AUTOSAR XML (schema 00049)
package /Application/DltConfig
  dlt log channel to process mapping DltLogChannelToProcessMapping_SOA_DriverSeat_TO_SOA_DriverSeat: dlt-log-channel=SOA_DriverSeat, process=SOA_DriverSeat
package /Application/Executable
  executable SOA_DriverSeat: category=APPLICATION_LEVEL, logging-behavior=USES-LOGGING, reporting-behavior=REPORTS-EXECUTION-STATE, version=1.0.0
    root sw component prototype AA: application-type=SOA_DriverSeat
package /Application/Manifest
  service instance to port prototype mapping SOA_DriverSeat_AA_PPort_SOA_DriverSeat: port-prototype=AA.PPort_SOA_DriverSeat, process=SOA_DriverSeat, service-instance=Provider_SoaDriverSeat
  service instance to port prototype mapping SOA_DriverSeat_AA_RPort_Zone1DrvSeat: port-prototype=AA.RPort_Zone1DrvSeat, process=SOA_DriverSeat, service-instance=Consumer_Zone1DrvSeat
  service instance to port prototype mapping SOA_DriverSeat_AA_RPort_Zone1VehicleInfo: port-prototype=AA.RPort_Zone1VehicleInfo, process=SOA_DriverSeat, service-instance=Consumer_SoaDriverSeat_VehicleInfo
package /Application/Package/SOA_DriverSeat/SoftwareCluster_1_0_0
  software cluster SOA_DriverSeat_SoftwareCluster: category=APPLICATION_LAYER, contained-ar-element=SOA_DriverSeat, contained-package-element=[SOA_DriverSeat_AA_PPort_SOA_DriverSeat, SOA_DriverSeat_AA_RPort_Zone1DrvSeat], contained-process=SOA_DriverSeat, vendor-id=79, vendor-signature=ParaCertificate, version=1.0.0
package /Application/Package/SOA_DriverSeat/SoftwareCluster_1_0_1
  software cluster SOA_DriverSeat_SoftwareCluster: category=APPLICATION_LAYER, contained-ar-element=SOA_DriverSeat, contained-package-element=[SOA_DriverSeat_AA_PPort_SOA_DriverSeat, SOA_DriverSeat_AA_RPort_Zone1DrvSeat], contained-process=SOA_DriverSeat, vendor-id=79, vendor-signature=ParaCertificate, version=1.0.1
package /Application/Package/SOA_DriverSeat/SoftwareCluster_1_0_2
  software cluster SOA_DriverSeat_SoftwareCluster: category=APPLICATION_LAYER, contained-ar-element=SOA_DriverSeat, contained-package-element=[SOA_DriverSeat_AA_PPort_SOA_DriverSeat, SOA_DriverSeat_AA_RPort_Zone1DrvSeat], contained-process=SOA_DriverSeat, vendor-id=79, vendor-signature=ParaCertificate, version=1.0.2
package /Application/Package/SOA_DriverSeat/SoftwarePackage
  software package SOA_DriverSeat_InstallSoftwarePackage_1_0_0: action-type=INSTALL, compressed-software-package-size=0, maximum-supported-ucm-version=1.0.0, minimum-supported-ucm-version=1.0.0, packager-id=79, packager-signature=ParaCertificate, post-verification-reboot=false, pre-activate=SC.Off, pre-activation-reboot=false, software-cluster=SoftwareCluster_1_0_0/SOA_DriverSeat_SoftwareCluster, uncompressed-software-cluster-size=0, verify=SC.Verify
  software package SOA_DriverSeat_RemoveSoftwarePackage_1_0_2: action-type=REMOVE, compressed-software-package-size=0, maximum-supported-ucm-version=1.0.0, minimum-supported-ucm-version=1.0.0, packager-id=79, packager-signature=ParaCertificate, post-verification-reboot=false, pre-activate=SC.Off, pre-activation-reboot=false, software-cluster=SoftwareCluster_1_0_2/SOA_DriverSeat_SoftwareCluster, uncompressed-software-cluster-size=0, verify=SC.Verify
  software package SOA_DriverSeat_UpdateSoftwarePackage_1_0_1: action-type=UPDATE, compressed-software-package-size=0, maximum-supported-ucm-version=1.0.0, minimum-supported-ucm-version=1.0.0, packager-id=79, packager-signature=ParaCertificate, post-verification-reboot=false, pre-activate=SC.Off, pre-activation-reboot=false, software-cluster=SoftwareCluster_1_0_1/SOA_DriverSeat_SoftwareCluster, uncompressed-software-cluster-size=0, verify=SC.Verify
package /Application/Package/SOA_DriverSeat/VehiclePackage
  vehicle package SOA_DriverSeat_InstallVehiclePackage_1_0_0: vehicle-driver-notification{approval-required=true, notification-state=PROCESS}, packager-signature=ParaCertificate
    rollout-qualifications:
      vehicle rollout step RolloutQualification0
        ucm-processings:
          ucm step UcmProcessing0: ucm=SOA_DriverSeat_InstallVehiclePackage_1_0_0/EEVP_UCM
            software package step SoftwarePackageStep0: process=SOA_DriverSeat_InstallSoftwarePackage_1_0_0, transfers=software-package-storing={storing=UCM, transfer=SOA_DriverSeat_InstallSoftwarePackage_1_0_0}
    ucm description EEVP_UCM: identifier=EEVP_UCM
  vehicle package SOA_DriverSeat_RemoveVehiclePackage_1_0_2: vehicle-driver-notification{approval-required=true, notification-state=PROCESS}, packager-signature=ParaCertificate
    rollout-qualifications:
      vehicle rollout step RolloutQualification0
        ucm-processings:
          ucm step UcmProcessing0: ucm=SOA_DriverSeat_RemoveVehiclePackage_1_0_2/EEVP_UCM
            software package step SoftwarePackageStep0: process=SOA_DriverSeat_RemoveSoftwarePackage_1_0_2, transfers=software-package-storing={storing=UCM, transfer=SOA_DriverSeat_RemoveSoftwarePackage_1_0_2}
    ucm description EEVP_UCM: identifier=EEVP_UCM
  vehicle package SOA_DriverSeat_UpdateVehiclePackage_1_0_1: vehicle-driver-notification{approval-required=true, notification-state=PROCESS}, packager-signature=ParaCertificate
    rollout-qualifications:
      vehicle rollout step RolloutQualification0
        ucm-processings:
          ucm step UcmProcessing0: ucm=SOA_DriverSeat_UpdateVehiclePackage_1_0_1/EEVP_UCM
            software package step SoftwarePackageStep0: process=SOA_DriverSeat_UpdateSoftwarePackage_1_0_1, transfers=software-package-storing={storing=UCM, transfer=SOA_DriverSeat_UpdateSoftwarePackage_1_0_1}
    ucm description EEVP_UCM: identifier=EEVP_UCM
package /Application/Process
  process SOA_DriverSeat: executable=SOA_DriverSeat, state-dependent-startup-config{function-group-state=[SC.On, SC.Verify], resource-group=DefaultResourceGroup, startup-config=SOA}
    process state machine SOA_DriverSeat: type=ProcessState
package /Application/SwComponent
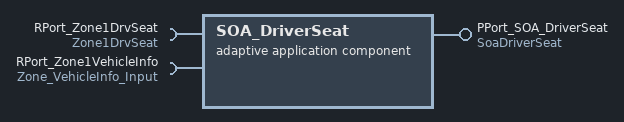
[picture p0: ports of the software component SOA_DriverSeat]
  adaptive application sw component type SOA_DriverSeat
    provide port PPort_SOA_DriverSeat: provided-interface=SoaDriverSeat
    require port RPort_Zone1DrvSeat: required-interface=Zone1DrvSeat
    require port RPort_Zone1VehicleInfo: required-interface=Zone_VehicleInfo_Input
